# EOS-S3 register map
File version: 0.1
CPU: CM4 r0p1, selectable endian, MPU, FPU, 3 interrupt priority bits
Registers are 32-bit, read-write, reset 0x0 unless marked. A register's access mark holds for its fields unless they carry their own. Offsets are from the block's base; lines under a group give offsets from that group; [hi:lo] are bit positions; {n}, {i} and the like mark numbered series; 'fields as' and 'values as' point back to an identical list; <NAME> marks a mode.

## Memory map
0x40004C00 IOMUX size 0x1B0 — IO Multiplexing Control
0x40006000 A1_Regs size 0x4 — Selects source APB Master to SPI Master between M4/AP and Fabric

## IOMUX — IO Multiplexing Control
Base 0x40004C00
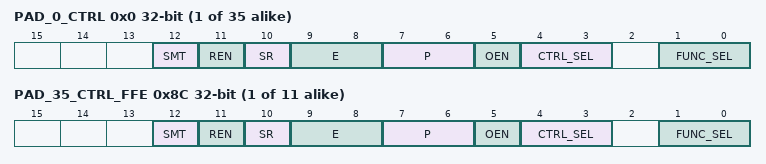
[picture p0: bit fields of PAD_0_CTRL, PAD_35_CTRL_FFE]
{0x0+4i} PAD_{i}_CTRL (i=0..34) — PAD_{i} control register
  [12] SMT — Schmitt Trigger
  [11] REN — Receive Enable
  [10] SR — Slew Rate
  [9:8] E — Driver Strenght
  [7:6] P — Driver state control
  [5] OEN — Active low output enable
  [4:3] CTRL_SEL — Control selection for IO Output. 0x0 = A0 registers, 0x1 = Others, 0x2 = Fabric
  [1:0] FUNC_SEL — Functional selection for IO output. Refer to IO Mux
{0x0+4i} PAD_{i}_CTRL_FFE (i=35..45) — PAD_{i} control register(ffe exclusive)
  [12] SMT — Schmitt Trigger
  [11] REN — Receive Enable
  [10] SR — Slew Rate
  [9:8] E — Driver Strenght
  [7:6] P — Driver state control
  [5] OEN — Active low output enable
  [4:3] CTRL_SEL — Control selection for IO Output. 0x0 = A0 registers, 0x1 = Others, 0x2 = Fabric. * Exception - when FUNC_SEL=2, the control is from FFE
  [1:0] FUNC_SEL — Functional selection for IO output. Refer to IO Mux

## Notices in the file
Apache License
Version 2.0, January 2004
http://www.apache.org/licenses
TERMS AND CONDITIONS FOR USE, REPRODUCTION, AND DISTRIBUTION
1. Definitions.
"License" shall mean the terms and conditions for use, reproduction,
and distribution as defined by Sections 1 through 9 of this document.
"Licensor" shall mean the copyright owner or entity authorized by
the copyright owner that is granting the License.
This SVD is based on the documentation provided by quicklogic on the EOS-S3 repository https://github.com/QuickLogic-Corp/EOS-S3. QuickLogic's documentation is licensed under the Apache 2.0 License, the same as the one provided for this SVD, but with QuickLogic as the copyright owner.
